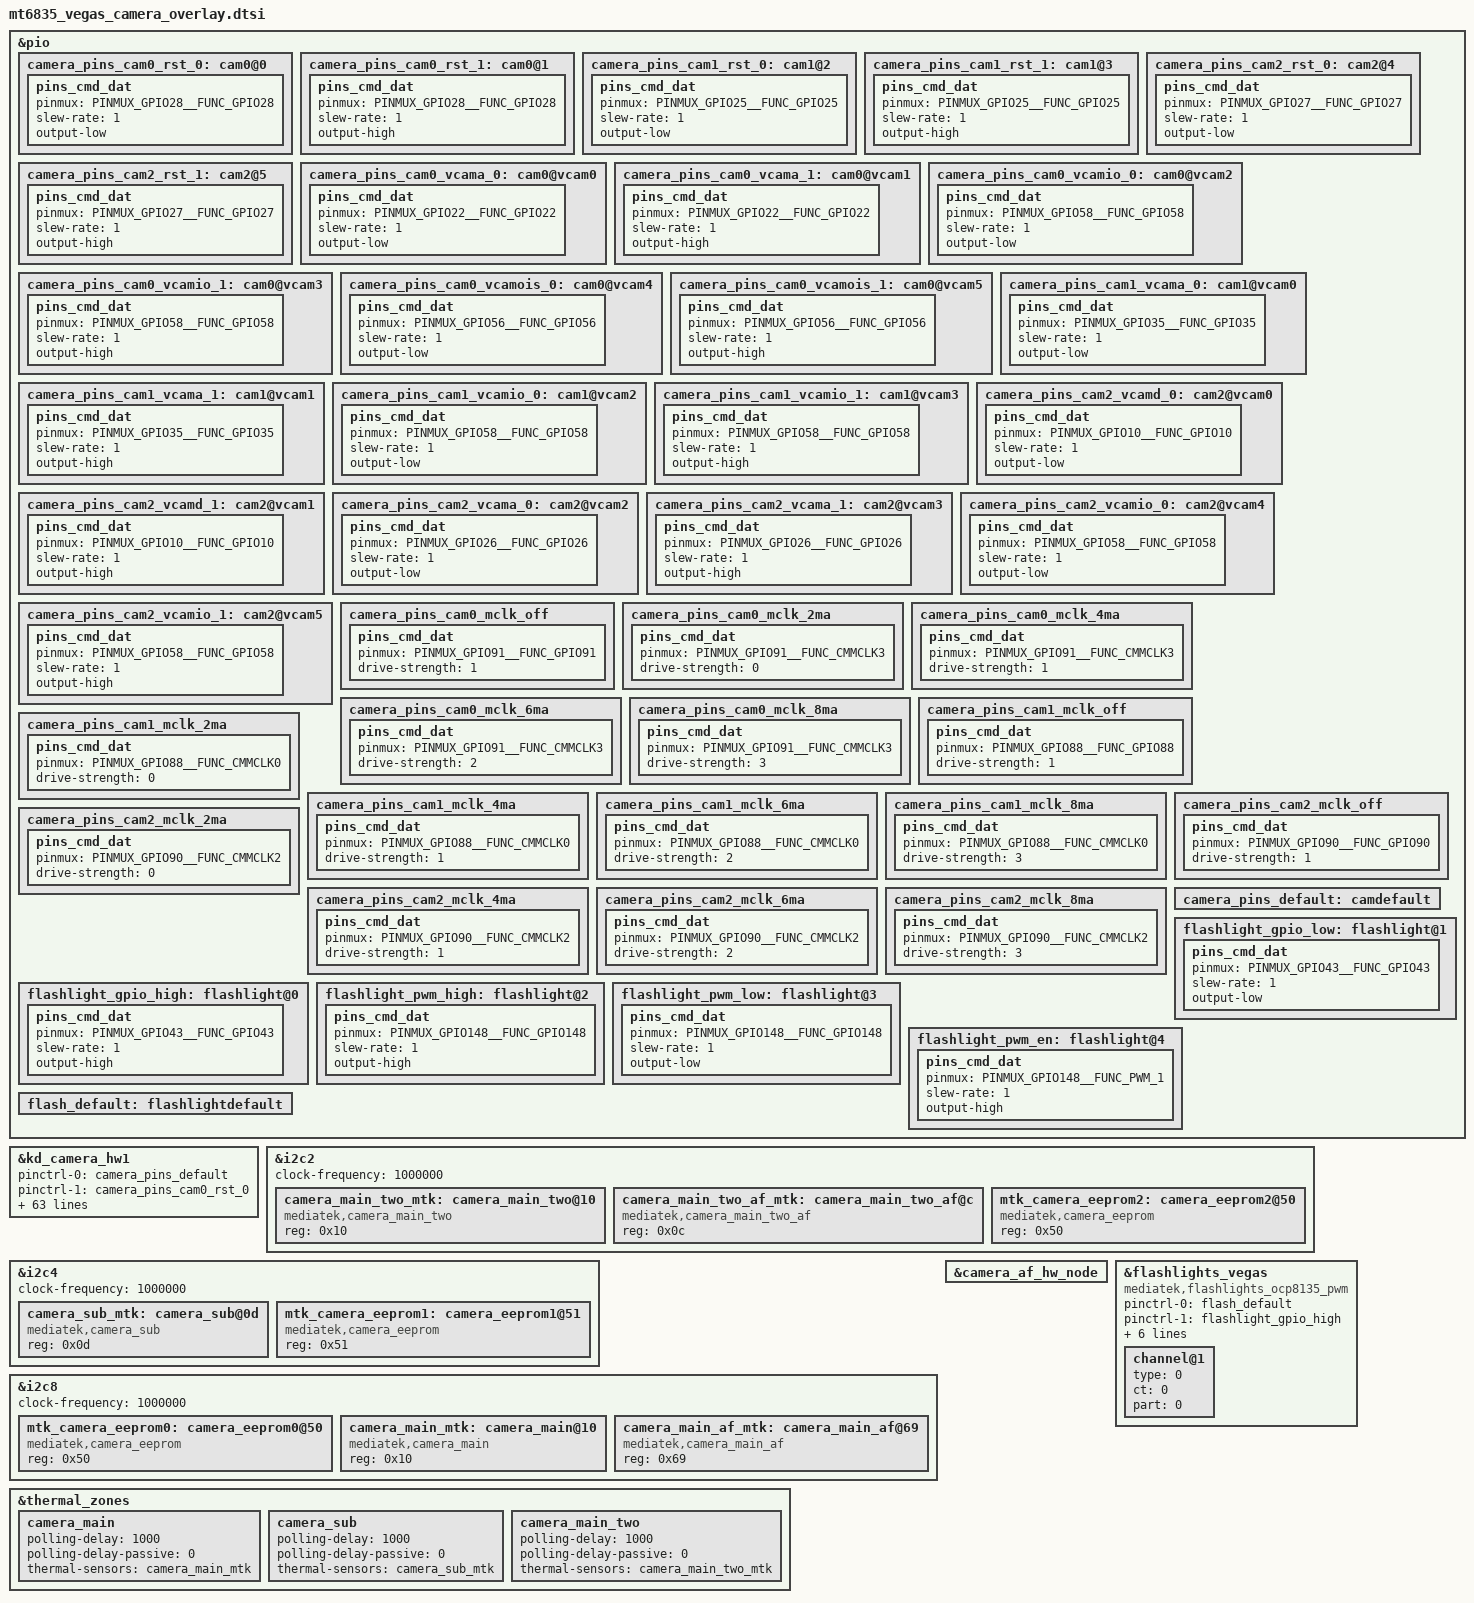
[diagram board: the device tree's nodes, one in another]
// SPDX-License-Identifier: GPL-2.0
/* Copyright (c) 2020 MediaTek Inc. */
/* CAMERA GPIO standardization */
&pio {
	camera_pins_cam0_rst_0: cam0@0 {
		pins_cmd_dat {
			pinmux = <PINMUX_GPIO28__FUNC_GPIO28>;
			slew-rate = <1>;
			output-low;
		};
	};
	camera_pins_cam0_rst_1: cam0@1 {
		pins_cmd_dat {
			pinmux = <PINMUX_GPIO28__FUNC_GPIO28>;
			slew-rate = <1>;
			output-high;
		};
	};
	camera_pins_cam1_rst_0: cam1@2 {
		pins_cmd_dat {
			pinmux = <PINMUX_GPIO25__FUNC_GPIO25>;
			slew-rate = <1>;
			output-low;
		};
	};
	camera_pins_cam1_rst_1: cam1@3 {
		pins_cmd_dat {
			pinmux = <PINMUX_GPIO25__FUNC_GPIO25>;
			slew-rate = <1>;
			output-high;
		};
	};
	camera_pins_cam2_rst_0: cam2@4 {
		pins_cmd_dat {
			pinmux = <PINMUX_GPIO27__FUNC_GPIO27>;
			slew-rate = <1>;
			output-low;
		};
	};
	camera_pins_cam2_rst_1: cam2@5 {
		pins_cmd_dat {
			pinmux = <PINMUX_GPIO27__FUNC_GPIO27>;
			slew-rate = <1>;
			output-high;
		};
	};
	camera_pins_cam0_vcama_0: cam0@vcam0 {
		pins_cmd_dat {
			pinmux = <PINMUX_GPIO22__FUNC_GPIO22>;
			slew-rate = <1>;
			output-low;
		};
	};
	camera_pins_cam0_vcama_1: cam0@vcam1 {
		pins_cmd_dat {
			pinmux = <PINMUX_GPIO22__FUNC_GPIO22>;
			slew-rate = <1>;
			output-high;
		};
	};
	camera_pins_cam0_vcamio_0: cam0@vcam2 {
		pins_cmd_dat {
			pinmux = <PINMUX_GPIO58__FUNC_GPIO58>;
			slew-rate = <1>;
			output-low;
		};
	};
	camera_pins_cam0_vcamio_1: cam0@vcam3  {
		pins_cmd_dat {
			pinmux = <PINMUX_GPIO58__FUNC_GPIO58>;
			slew-rate = <1>;
			output-high;
		};
	};
	camera_pins_cam0_vcamois_0: cam0@vcam4 {
		pins_cmd_dat {
			pinmux = <PINMUX_GPIO56__FUNC_GPIO56>;
			slew-rate = <1>;
			output-low;
		};
	};
	camera_pins_cam0_vcamois_1: cam0@vcam5 {
		pins_cmd_dat {
			pinmux = <PINMUX_GPIO56__FUNC_GPIO56>;
			slew-rate = <1>;
			output-high;
		};
	};
	camera_pins_cam1_vcama_0: cam1@vcam0 {
		pins_cmd_dat {
			pinmux = <PINMUX_GPIO35__FUNC_GPIO35>;
			slew-rate = <1>;
			output-low;
		};
	};
	camera_pins_cam1_vcama_1: cam1@vcam1 {
		pins_cmd_dat {
			pinmux = <PINMUX_GPIO35__FUNC_GPIO35>;
			slew-rate = <1>;
			output-high;
		};
	};
	camera_pins_cam1_vcamio_0: cam1@vcam2 {
		pins_cmd_dat {
			pinmux = <PINMUX_GPIO58__FUNC_GPIO58>;
			slew-rate = <1>;
			output-low;
		};
	};
	camera_pins_cam1_vcamio_1: cam1@vcam3 {
		pins_cmd_dat {
			pinmux = <PINMUX_GPIO58__FUNC_GPIO58>;
			slew-rate = <1>;
			output-high;
		};
	};
	camera_pins_cam2_vcamd_0: cam2@vcam0 {
		pins_cmd_dat {
			pinmux = <PINMUX_GPIO10__FUNC_GPIO10>;
			slew-rate = <1>;
			output-low;
		};
	};
	camera_pins_cam2_vcamd_1: cam2@vcam1 {
		pins_cmd_dat {
			pinmux = <PINMUX_GPIO10__FUNC_GPIO10>;
			slew-rate = <1>;
			output-high;
		};
	};
	camera_pins_cam2_vcama_0: cam2@vcam2 {
		pins_cmd_dat {
			pinmux = <PINMUX_GPIO26__FUNC_GPIO26>;
			slew-rate = <1>;
			output-low;
		};
	};
	camera_pins_cam2_vcama_1: cam2@vcam3 {
		pins_cmd_dat {
			pinmux = <PINMUX_GPIO26__FUNC_GPIO26>;
			slew-rate = <1>;
			output-high;
		};
	};
	camera_pins_cam2_vcamio_0: cam2@vcam4 {
		pins_cmd_dat {
			pinmux = <PINMUX_GPIO58__FUNC_GPIO58>;
			slew-rate = <1>;
			output-low;
		};
	};
	camera_pins_cam2_vcamio_1: cam2@vcam5 {
		pins_cmd_dat {
			pinmux = <PINMUX_GPIO58__FUNC_GPIO58>;
			slew-rate = <1>;
			output-high;
		};
	};
	camera_pins_cam0_mclk_off: camera_pins_cam0_mclk_off {
		pins_cmd_dat {
			pinmux = <PINMUX_GPIO91__FUNC_GPIO91>;
			drive-strength = <1>;
		};
	};
	camera_pins_cam0_mclk_2ma: camera_pins_cam0_mclk_2ma {
		pins_cmd_dat {
			pinmux = <PINMUX_GPIO91__FUNC_CMMCLK3>;
			drive-strength = <0>;
		};
	};
	camera_pins_cam0_mclk_4ma: camera_pins_cam0_mclk_4ma {
		pins_cmd_dat {
			pinmux = <PINMUX_GPIO91__FUNC_CMMCLK3>;
			drive-strength = <1>;
		};
	};
	camera_pins_cam0_mclk_6ma: camera_pins_cam0_mclk_6ma {
		pins_cmd_dat {
			pinmux = <PINMUX_GPIO91__FUNC_CMMCLK3>;
			drive-strength = <2>;
		};
	};
	camera_pins_cam0_mclk_8ma: camera_pins_cam0_mclk_8ma {
		pins_cmd_dat {
			pinmux = <PINMUX_GPIO91__FUNC_CMMCLK3>;
			drive-strength = <3>;
		};
	};
	camera_pins_cam1_mclk_off: camera_pins_cam1_mclk_off {
		pins_cmd_dat {
			pinmux = <PINMUX_GPIO88__FUNC_GPIO88>;
			drive-strength = <1>;
		};
	};
	camera_pins_cam1_mclk_2ma: camera_pins_cam1_mclk_2ma {
		pins_cmd_dat {
			pinmux = <PINMUX_GPIO88__FUNC_CMMCLK0>;
			drive-strength = <0>;
		};
	};
	camera_pins_cam1_mclk_4ma: camera_pins_cam1_mclk_4ma {
		pins_cmd_dat {
			pinmux = <PINMUX_GPIO88__FUNC_CMMCLK0>;
			drive-strength = <1>;
		};
	};
	camera_pins_cam1_mclk_6ma: camera_pins_cam1_mclk_6ma {
		pins_cmd_dat {
			pinmux = <PINMUX_GPIO88__FUNC_CMMCLK0>;
			drive-strength = <2>;
		};
	};
	camera_pins_cam1_mclk_8ma: camera_pins_cam1_mclk_8ma {
		pins_cmd_dat {
			pinmux = <PINMUX_GPIO88__FUNC_CMMCLK0>;
			drive-strength = <3>;
		};
	};
	camera_pins_cam2_mclk_off: camera_pins_cam2_mclk_off {
		pins_cmd_dat {
			pinmux = <PINMUX_GPIO90__FUNC_GPIO90>;
			drive-strength = <1>;
		};
	};
	camera_pins_cam2_mclk_2ma: camera_pins_cam2_mclk_2ma {
		pins_cmd_dat {
			pinmux = <PINMUX_GPIO90__FUNC_CMMCLK2>;
			drive-strength = <0>;
		};
	};
	camera_pins_cam2_mclk_4ma: camera_pins_cam2_mclk_4ma {
		pins_cmd_dat {
			pinmux = <PINMUX_GPIO90__FUNC_CMMCLK2>;
			drive-strength = <1>;
		};
	};
	camera_pins_cam2_mclk_6ma: camera_pins_cam2_mclk_6ma {
		pins_cmd_dat {
			pinmux = <PINMUX_GPIO90__FUNC_CMMCLK2>;
			drive-strength = <2>;
		};
	};
	camera_pins_cam2_mclk_8ma: camera_pins_cam2_mclk_8ma {
		pins_cmd_dat {
			pinmux = <PINMUX_GPIO90__FUNC_CMMCLK2>;
			drive-strength = <3>;
		};
	};
	camera_pins_default: camdefault {
	};

	flashlight_gpio_high: flashlight@0 {
		pins_cmd_dat {
			pinmux = <PINMUX_GPIO43__FUNC_GPIO43>;
			slew-rate = <1>;
			output-high;
		};
	};
	flashlight_gpio_low: flashlight@1 {
		pins_cmd_dat {
			pinmux = <PINMUX_GPIO43__FUNC_GPIO43>;
			slew-rate = <1>;
			output-low;
		};
	};
	flashlight_pwm_high: flashlight@2 {
		pins_cmd_dat {
			pinmux = <PINMUX_GPIO148__FUNC_GPIO148>;
			slew-rate = <1>;
			output-high;
		};
	};
	flashlight_pwm_low: flashlight@3 {
		pins_cmd_dat {
			pinmux = <PINMUX_GPIO148__FUNC_GPIO148>;
			slew-rate = <1>;
			output-low;
		};
	};
	flashlight_pwm_en: flashlight@4 {
		pins_cmd_dat {
			pinmux = <PINMUX_GPIO148__FUNC_PWM_1>;
			slew-rate = <1>;
			output-high;
		};
	};
	flash_default: flashlightdefault {
	};
};
&kd_camera_hw1 {
	pinctrl-names = "default",
			"cam0_rst0", "cam0_rst1",
			"cam1_rst0", "cam1_rst1",
			"cam2_rst0", "cam2_rst1",
			"cam0_ldo_vcama_0",  "cam0_ldo_vcama_1",
			"cam0_ldo_vcamio_0", "cam0_ldo_vcamio_1",
			"cam1_ldo_vcama_0",  "cam1_ldo_vcama_1",
			"cam1_ldo_vcamio_0", "cam1_ldo_vcamio_1",
			"cam2_ldo_vcamd_0",  "cam2_ldo_vcamd_1",
		    "cam2_ldo_vcama_0",  "cam2_ldo_vcama_1",
	        "cam2_ldo_vcamio_0", "cam2_ldo_vcamio_1",
			"cam0_mclk_off",
			"cam0_mclk_2mA", "cam0_mclk_4mA",
			"cam0_mclk_6mA", "cam0_mclk_8mA",
			"cam1_mclk_off",
			"cam1_mclk_2mA", "cam1_mclk_4mA",
			"cam1_mclk_6mA", "cam1_mclk_8mA",
			"cam2_mclk_off",
			"cam2_mclk_2mA", "cam2_mclk_4mA",
			"cam2_mclk_6mA", "cam2_mclk_8mA",
			"cam0_ldo_vcamois_0", "cam0_ldo_vcamois_1";

	pinctrl-0 = <&camera_pins_default>;
	pinctrl-1 = <&camera_pins_cam0_rst_0>;
	pinctrl-2 = <&camera_pins_cam0_rst_1>;
	pinctrl-3 = <&camera_pins_cam1_rst_0>;
	pinctrl-4 = <&camera_pins_cam1_rst_1>;
	pinctrl-5 = <&camera_pins_cam2_rst_0>;
	pinctrl-6 = <&camera_pins_cam2_rst_1>;
	pinctrl-7 = <&camera_pins_cam0_vcama_0>;
	pinctrl-8 = <&camera_pins_cam0_vcama_1>;
	pinctrl-9 = <&camera_pins_cam0_vcamio_0>;
	pinctrl-10 = <&camera_pins_cam0_vcamio_1>;
	pinctrl-11 = <&camera_pins_cam1_vcama_0>;
	pinctrl-12 = <&camera_pins_cam1_vcama_1>;
	pinctrl-13 = <&camera_pins_cam1_vcamio_0>;
	pinctrl-14 = <&camera_pins_cam1_vcamio_1>;
	pinctrl-15 = <&camera_pins_cam2_vcamd_0>;
	pinctrl-16 = <&camera_pins_cam2_vcamd_1>;
	pinctrl-17 = <&camera_pins_cam2_vcama_0>;
	pinctrl-18 = <&camera_pins_cam2_vcama_1>;
	pinctrl-19 = <&camera_pins_cam2_vcamio_0>;
	pinctrl-20 = <&camera_pins_cam2_vcamio_1>;
	pinctrl-21 = <&camera_pins_cam0_mclk_off>;
	pinctrl-22 = <&camera_pins_cam0_mclk_2ma>;
	pinctrl-23 = <&camera_pins_cam0_mclk_4ma>;
	pinctrl-24 = <&camera_pins_cam0_mclk_6ma>;
	pinctrl-25 = <&camera_pins_cam0_mclk_8ma>;
	pinctrl-26 = <&camera_pins_cam1_mclk_off>;
	pinctrl-27 = <&camera_pins_cam1_mclk_2ma>;
	pinctrl-28 = <&camera_pins_cam1_mclk_4ma>;
	pinctrl-29 = <&camera_pins_cam1_mclk_6ma>;
	pinctrl-30 = <&camera_pins_cam1_mclk_8ma>;
	pinctrl-31 = <&camera_pins_cam2_mclk_off>;
	pinctrl-32 = <&camera_pins_cam2_mclk_2ma>;
	pinctrl-33 = <&camera_pins_cam2_mclk_4ma>;
	pinctrl-34 = <&camera_pins_cam2_mclk_6ma>;
	pinctrl-35 = <&camera_pins_cam2_mclk_8ma>;
	pinctrl-36 = <&camera_pins_cam0_vcamois_0>;
	pinctrl-37 = <&camera_pins_cam0_vcamois_1>;

	cam0_vcamd-supply = <&cam_dvdd_rear_main>;
	cam0_vcamaf-supply = <&cam_afvdd_rear_main>;
	cam1_vcamd-supply = <&cam_dvdd_front>;
	cam2_vcamaf-supply = <&cam_afvdd_rear_wide>;

	cam0_pin_mclk = "mclk";
	cam0_pin_rst = "gpio";
	cam0_pin_vcama = "gpio";
	cam0_pin_vcamio = "gpio";
	cam0_pin_vcamd = "regulator";
	cam0_pin_vcamois = "gpio";
	cam0_pin_vcamaf = "regulator";
	cam1_pin_mclk = "mclk";
	cam1_pin_rst = "gpio";
	cam1_pin_vcama = "gpio";
	cam1_pin_vcamio = "gpio";
	cam1_pin_vcamd = "regulator";
	cam2_pin_mclk = "mclk";
	cam2_pin_rst = "gpio";
	cam2_pin_vcama = "gpio";
	cam2_pin_vcamio = "gpio";
	cam2_pin_vcamd = "gpio";
	cam2_pin_vcamaf = "regulator";

	cam0_enable_sensor = "mot_vegas_ov50d_mipi_raw";
	cam1_enable_sensor = "mot_vegas_s5k3p9_mipi_raw";
	cam2_enable_sensor = "mot_vegas_ov08d_mipi_raw";
	status = "okay";
};
/* CAMERA GPIO end */

/* CAMERA EEPROM */
&i2c2 {
	status = "okay";
	clock-frequency = <1000000>;
	#address-cells = <1>;
	#size-cells = <0>;

	camera_main_two_mtk:camera_main_two@10 {
		compatible = "mediatek,camera_main_two";
		#thermal-sensor-cells = <0>;
		reg = <0x10>;
		status = "okay";
	};
	camera_main_two_af_mtk:camera_main_two_af@c {
		compatible = "mediatek,camera_main_two_af";
		reg = <0x0c>;
		status = "okay";
	};
	mtk_camera_eeprom2:camera_eeprom2@50 {
		compatible = "mediatek,camera_eeprom";
		reg = <0x50>;
		status = "okay";
	};
};
&i2c4 {
	status = "okay";
	clock-frequency = <1000000>;
	#address-cells = <1>;
	#size-cells = <0>;

	camera_sub_mtk:camera_sub@0d {
		compatible = "mediatek,camera_sub";
		#thermal-sensor-cells = <0>;
		reg = <0x0d>;
		status = "okay";
	};

	mtk_camera_eeprom1:camera_eeprom1@51 {
		compatible = "mediatek,camera_eeprom";
		reg = <0x51>;
		status = "okay";
	};

};
&i2c8 {
	status = "okay";
	clock-frequency = <1000000>;
	#address-cells = <1>;
	#size-cells = <0>;

	mtk_camera_eeprom0:camera_eeprom0@50 {
		compatible = "mediatek,camera_eeprom";
		reg = <0x50>;
		status = "okay";
	};
	camera_main_mtk:camera_main@10 {
		compatible = "mediatek,camera_main";
		#thermal-sensor-cells = <0>;
		reg = <0x10>;
		status = "okay";
	};
};
/* CAMERA EEPROM end */

/* CAMERA AF */
&i2c8 {
	camera_main_af_mtk:camera_main_af@69 {
		compatible = "mediatek,camera_main_af";
		reg = <0x69>;
		status = "okay";
	};
};

&i2c2 {

};
&camera_af_hw_node {
	status = "okay";
};
/* CAMERA AF end */

/* CAMERA TZ config */
&thermal_zones {
	camera_main: camera_main {
		polling-delay = <1000>; /* milliseconds */
		polling-delay-passive = <0>; /* milliseconds */
		thermal-sensors = <&camera_main_mtk>;
	};
	camera_sub: camera_sub {
		polling-delay = <1000>; /* milliseconds */
		polling-delay-passive = <0>; /* milliseconds */
		thermal-sensors = <&camera_sub_mtk>;
	};
	camera_main_two: camera_main_two {
		polling-delay = <1000>; /* milliseconds */
		polling-delay-passive = <0>; /* milliseconds */
		thermal-sensors = <&camera_main_two_mtk>;
	};
};
/* CAMERA TZ config end */
&kd_camera_hw1 {
       cust-sensor = "mot_vegas_ov50d_mipi_raw mot_vegas_s5k3p9_mipi_raw mot_vegas_ov08d_mipi_raw";
};

/* CAMERA Flashlight */
&flashlights_vegas {
	compatible = "mediatek,flashlights_ocp8135_pwm";
	pinctrl-names = "default",
		"flashlight_gpio_high",
		"flashlight_gpio_low",
		"flashlight_pwm_high",
		"flashlight_pwm_low",
		"flashlight_pwm_en";

	pinctrl-0 = <&flash_default>;
	pinctrl-1 = <&flashlight_gpio_high>;
	pinctrl-2 = <&flashlight_gpio_low>;
	pinctrl-3 = <&flashlight_pwm_high>;
	pinctrl-4 = <&flashlight_pwm_low>;
	pinctrl-5 = <&flashlight_pwm_en>;
        srcclk = <&pericfg_ao_clk>;

	decouple = <1>;
	channel@1 {
                status = "okay";
		type = <0>;
		ct = <0>;
		part = <0>;
	};
};
/* CAMERA Flashlight end */
